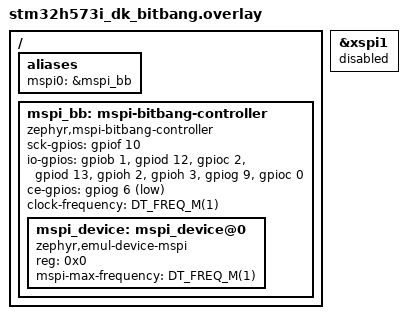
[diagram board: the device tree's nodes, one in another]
/*
 * Copyright The Zephyr Project Contributors
 *
 * SPDX-License-Identifier: Apache-2.0
 */

/*
 * Bitbang MSPI controller on the OCTOSPI1 pins of the STM32H573I-DK, which
 * the hardware controller and its flash device must release.
 */

/delete-node/ &ext_flash_ctrl;

&xspi1 {
	status = "disabled";
};

/ {
	aliases {
		mspi0 = &mspi_bb;
	};

	mspi_bb: mspi-bitbang-controller {
		compatible = "zephyr,mspi-bitbang-controller";
		#address-cells = <1>;
		#size-cells = <0>;
		status = "okay";
		sck-gpios = <&gpiof 10 GPIO_ACTIVE_HIGH>;
		io-gpios = <&gpiob 1 GPIO_ACTIVE_HIGH>, <&gpiod 12 GPIO_ACTIVE_HIGH>,
			   <&gpioc 2 GPIO_ACTIVE_HIGH>, <&gpiod 13 GPIO_ACTIVE_HIGH>,
			   <&gpioh 2 GPIO_ACTIVE_HIGH>, <&gpioh 3 GPIO_ACTIVE_HIGH>,
			   <&gpiog 9 GPIO_ACTIVE_HIGH>, <&gpioc 0 GPIO_ACTIVE_HIGH>;
		ce-gpios = <&gpiog 6 GPIO_ACTIVE_LOW>;
		clock-frequency = <DT_FREQ_M(1)>;

		mspi_device: mspi_device@0 {
			status = "okay";
			compatible = "zephyr,emul-device-mspi";
			reg = <0x0>;
			mspi-max-frequency = <DT_FREQ_M(1)>;
		};
	};
};
